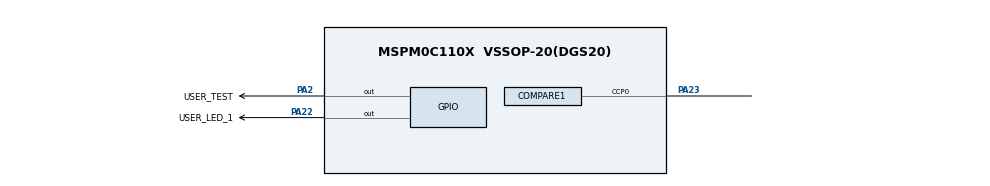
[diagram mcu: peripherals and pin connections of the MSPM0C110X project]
// @cliArgs --device "MSPM0C110X" --package "VSSOP-20(DGS20)" --part "Default"
// @cliArgs --board /ti/boards/LP_MSPM0C1104 --rtos nortos

/**
 * Import the modules used in this configuration.
 */
const COMPARE  = scripting.addModule("/ti/driverlib/COMPARE", {}, false);
const COMPARE1 = COMPARE.addInstance();
const GPIO     = scripting.addModule("/ti/driverlib/GPIO", {}, false);
const GPIO1    = GPIO.addInstance();
const SYSCTL   = scripting.addModule("/ti/driverlib/SYSCTL");

/**
 * Write custom configuration values to the imported modules.
 */
COMPARE1.$name                      = "COMPARE_0";
COMPARE1.timerPeriod                = 5;
COMPARE1.interrupts                 = ["LOAD"];
COMPARE1.peripheral.$assign         = "TIMG14";
COMPARE1.peripheral.ccp0Pin.$assign = "PA23";

const Board = scripting.addModule("/ti/driverlib/Board", {}, false);

GPIO1.$name                                 = "GPIO_LEDS";
GPIO1.associatedPins.create(2);
GPIO1.associatedPins[0].$name               = "USER_LED_1";
GPIO1.associatedPins[0].assignedPort        = "PORTA";
GPIO1.associatedPins[0].pin.$assign         = "PA22";
GPIO1.associatedPins[0].initialValue        = "SET";
GPIO1.associatedPins[1].assignedPort        = "PORTA";
GPIO1.associatedPins[1].assignedPortSegment = "Lower";
GPIO1.associatedPins[1].$name               = "USER_TEST";
GPIO1.associatedPins[1].pin.$assign         = "PA2";
GPIO1.associatedPins[1].initialValue        = "SET";

SYSCTL.clockTreeEn = true;
